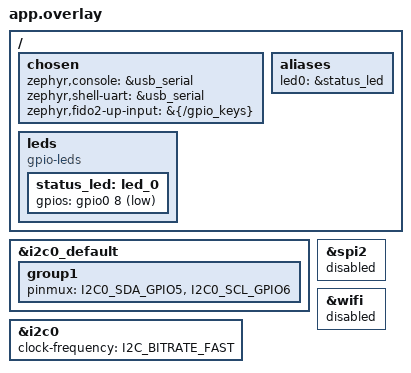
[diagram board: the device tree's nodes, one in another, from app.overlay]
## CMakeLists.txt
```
# SPDX-License-Identifier: Apache-2.0
cmake_minimum_required(VERSION 3.28.0)
find_package(Zephyr REQUIRED HINTS $ENV{ZEPHYR_BASE})
project(diy_fido_ble)
set(U8G2_ROOT ${CMAKE_CURRENT_SOURCE_DIR}/../vendor/u8g2)
file(GLOB U8G2_SOURCES ${U8G2_ROOT}/csrc/*.c)
target_sources(app PRIVATE src/main.c src/oled.c src/user_presence.c src/key_import.c ${U8G2_SOURCES})
target_include_directories(app PRIVATE ${U8G2_ROOT}/csrc src)
```

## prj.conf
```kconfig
CONFIG_FIDO2=y
CONFIG_FIDO2_TRANSPORT_BLE=y
CONFIG_FIDO2_AAGUID="25497c3c8433453eacfc9dd2c04e8e15"
CONFIG_FIDO2_BLE_REQUIRE_AUTHENTICATED_LINK=y
CONFIG_FIDO2_UP_CUSTOM=y
CONFIG_FIDO2_LOG_LEVEL_INF=y
CONFIG_BT=y
CONFIG_BT_PERIPHERAL=y
CONFIG_BT_SMP=y
CONFIG_BT_SETTINGS=y
CONFIG_BT_BONDING_REQUIRED=y
# Keep bonds for five PCs; a sixth must not silently evict an existing PC.
CONFIG_BT_MAX_PAIRED=5
CONFIG_BT_MAX_CONN=1
CONFIG_BT_KEYS_OVERWRITE_OLDEST=n
CONFIG_BT_USER_CONN_PARAM_REJECTED=y
CONFIG_BT_GATT_ENFORCE_SUBSCRIPTION=y
CONFIG_BT_DIS=y
CONFIG_BT_DIS_FW_REV=y
CONFIG_BT_DIS_MANUF_NAME_STR="DIY FIDO"
CONFIG_BT_DIS_MODEL_NUMBER_STR="ESP32-C3 OLED"
CONFIG_BT_DIS_FW_REV_STR="0.1"
CONFIG_BT_DEVICE_NAME="DIY FIDO C3"
CONFIG_BT_RX_STACK_SIZE=3072
CONFIG_BT_PERIPHERAL_PREF_MIN_INT=24
CONFIG_BT_PERIPHERAL_PREF_MAX_INT=40
CONFIG_BT_PERIPHERAL_PREF_LATENCY=0
CONFIG_BT_PERIPHERAL_PREF_TIMEOUT=400
CONFIG_FLASH=y
CONFIG_FLASH_MAP=y
CONFIG_NVS=y
CONFIG_SETTINGS=y
CONFIG_SETTINGS_NVS=y
CONFIG_SECURE_STORAGE_ITS_MAX_DATA_SIZE=1024
CONFIG_GPIO=y
CONFIG_INPUT=y
CONFIG_I2C=y
CONFIG_LOG=y
CONFIG_SERIAL=y
CONFIG_CONSOLE=y
CONFIG_UART_CONSOLE=y
CONFIG_MAIN_STACK_SIZE=8192
CONFIG_SYSTEM_WORKQUEUE_STACK_SIZE=4096
CONFIG_HEAP_MEM_POOL_SIZE=32768

# Crypto and controller tasks need headroom on the ESP32-C3 port.
CONFIG_FIDO2_THREAD_STACK_SIZE=8192
CONFIG_ESP32_BT_CONTROLLER_STACK_SIZE=8192
CONFIG_STACK_SENTINEL=y
CONFIG_INIT_STACKS=y
CONFIG_LOG_BUFFER_SIZE=4096

CONFIG_REBOOT=y
```

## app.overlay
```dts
#include <zephyr/dt-bindings/pinctrl/esp32c3-pinctrl.h>

/ {
    chosen {
        zephyr,console = &usb_serial;
        zephyr,shell-uart = &usb_serial;
        zephyr,fido2-up-input = &{/gpio_keys};
    };
    aliases {
        led0 = &status_led;
    };
    leds {
        compatible = "gpio-leds";
        status_led: led_0 {
            gpios = <&gpio0 8 GPIO_ACTIVE_LOW>;
        };
    };
};

&i2c0_default {
    group1 {
        pinmux = <I2C0_SDA_GPIO5>, <I2C0_SCL_GPIO6>;
    };
};

&i2c0 { clock-frequency = <I2C_BITRATE_FAST>; };

&spi2 { status = "disabled"; };
&wifi { status = "disabled"; };
```

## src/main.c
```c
/* SPDX-License-Identifier: Apache-2.0 */
#include <zephyr/kernel.h>
#include <zephyr/logging/log.h>
#include <zephyr/drivers/gpio.h>
#include <zephyr/bluetooth/bluetooth.h>
#include <zephyr/bluetooth/conn.h>
#include <zephyr/bluetooth/uuid.h>
#include <zephyr/settings/settings.h>
#include <zephyr/authentication/fido2/fido2.h>
#include <zephyr/authentication/fido2/fido2_transport.h>
#include <zephyr/sys/atomic.h>
#include <stdio.h>
#include <esp_bt.h>
#include <zephyr/input/input.h>
#include "oled.h"
#include "key_import.h"

LOG_MODULE_REGISTER(diy_fido, LOG_LEVEL_INF);
static const struct gpio_dt_spec led = GPIO_DT_SPEC_GET(DT_ALIAS(led0), gpios);
static K_MUTEX_DEFINE(pairing_lock);
static struct bt_conn *pairing_conn;
static atomic_t state;
static atomic_t passkey = ATOMIC_INIT(-1);
static atomic_t connected;
static atomic_t comparison_pressed;

static void comparison_button(struct input_event *evt, void *data)
{
    ARG_UNUSED(data);
    if (evt->type == INPUT_EV_KEY && evt->code == INPUT_KEY_0 &&
        evt->value == 1 && atomic_get(&passkey) >= 0) {
        atomic_set(&comparison_pressed, 1);
    }
}
INPUT_CALLBACK_DEFINE(DEVICE_DT_GET(DT_CHOSEN(zephyr_fido2_up_input)),
                      comparison_button, NULL);
static void clear_pairing(void);

static const struct bt_data ad[] = {
    BT_DATA_BYTES(BT_DATA_FLAGS, BT_LE_AD_GENERAL | BT_LE_AD_NO_BREDR),
    BT_DATA_BYTES(BT_DATA_UUID16_ALL, BT_UUID_16_ENCODE(FIDO2_BLE_SERVICE_UUID_VAL)),
};
static const uint8_t service_data[] = {
    BT_UUID_16_ENCODE(FIDO2_BLE_SERVICE_UUID_VAL), FIDO2_BLE_SERVICE_DATA_PAIRING_MODE,
};
static const struct bt_data sd[] = {
    BT_DATA(BT_DATA_SVC_DATA16, service_data, sizeof(service_data)),
    BT_DATA(BT_DATA_NAME_COMPLETE, CONFIG_BT_DEVICE_NAME, sizeof(CONFIG_BT_DEVICE_NAME) - 1),
};

static void advertise(void)
{
    int err = bt_le_adv_start(BT_LE_ADV_CONN_FAST_1, ad, ARRAY_SIZE(ad), sd, ARRAY_SIZE(sd));
    LOG_INF("BLE advertising result=%d", err);
}
static void on_connected(struct bt_conn *conn, uint8_t err)
{
    ARG_UNUSED(conn);
    atomic_set(&connected, err == 0);
    LOG_INF("BLE connected result=%u", err);
    if (err == 0) {
        int security_err = bt_conn_set_security(conn, BT_SECURITY_L3);
        LOG_INF("BLE security request=%d", security_err);
    }
}
static void on_disconnected(struct bt_conn *conn, uint8_t reason)
{
    ARG_UNUSED(conn);
    atomic_clear(&connected);
    clear_pairing();
    LOG_INF("BLE disconnected reason=%u", reason);
}
static void on_recycled(void) { advertise(); }
static void on_security(struct bt_conn *conn, bt_security_t level, enum bt_security_err err)
{
    ARG_UNUSED(conn);
    LOG_INF("BLE security level=%u result=%u", level, err);
}
BT_CONN_CB_DEFINE(connection_callbacks) = {
    .connected = on_connected, .disconnected = on_disconnected, .recycled = on_recycled,
    .security_changed = on_security,
};

static void display_passkey(struct bt_conn *conn, unsigned int key)
{
    ARG_UNUSED(conn);
    atomic_set(&passkey, key);
    LOG_INF("BLE pairing: passkey shown on OLED");
}
static void confirm_passkey(struct bt_conn *conn, unsigned int key)
{
    k_mutex_lock(&pairing_lock, K_FOREVER);
    if (pairing_conn) { bt_conn_unref(pairing_conn); }
    pairing_conn = bt_conn_ref(conn);
    atomic_clear(&comparison_pressed);
    atomic_set(&passkey, key);
    k_mutex_unlock(&pairing_lock);
    LOG_INF("BLE numeric comparison: compare OLED PIN and press BOOT");
}
static void clear_pairing(void)
{
    k_mutex_lock(&pairing_lock, K_FOREVER);
    if (pairing_conn) { bt_conn_unref(pairing_conn); pairing_conn = NULL; }
    atomic_set(&passkey, -1);
    atomic_clear(&comparison_pressed);
    k_mutex_unlock(&pairing_lock);
}
static void pairing_cancel(struct bt_conn *conn)
{
    ARG_UNUSED(conn);
    clear_pairing();
}
static void pairing_complete(struct bt_conn *conn, bool bonded)
{
    ARG_UNUSED(conn);
    clear_pairing();
    LOG_INF("BLE pairing completed bonded=%d", bonded);
}
static void pairing_failed(struct bt_conn *conn, enum bt_security_err reason)
{
    ARG_UNUSED(conn);
    clear_pairing();
    LOG_WRN("BLE pairing failed reason=%u", reason);
}
static const struct bt_conn_auth_cb auth_callbacks = {
    .passkey_display = display_passkey, .passkey_confirm = confirm_passkey,
    .cancel = pairing_cancel,
};
static struct bt_conn_auth_info_cb auth_info_callbacks = {
    .pairing_complete = pairing_complete, .pairing_failed = pairing_failed,
};

static void state_changed(enum fido2_runtime_state current, void *data)
{
    ARG_UNUSED(data);
    atomic_set(&state, current);
    LOG_INF("FIDO state=%d", current);
}

int main(void)
{
    int err;
    oled_init();
    gpio_pin_configure_dt(&led, GPIO_OUTPUT_INACTIVE);
    err = fido2_init();
    if (err) { LOG_ERR("FIDO init=%d", err); oled_status("Init failed", "See USB log"); return err; }
    key_import_boot_mode();
    fido2_set_state_callback(state_changed, NULL);
    err = fido2_start();
    if (err) { return err; }
    bt_conn_auth_cb_register(&auth_callbacks);
    bt_conn_auth_info_cb_register(&auth_info_callbacks);
    err = bt_enable(NULL);
    if (err) { LOG_ERR("BLE init=%d", err); return err; }
    err = settings_load();
    if (err) { LOG_ERR("Settings load=%d", err); return err; }
    err = esp_ble_tx_power_set(ESP_BLE_PWR_TYPE_DEFAULT, ESP_PWR_LVL_P9);
    LOG_INF("BLE default TX power +9 dBm result=%d", err);
    err = esp_ble_tx_power_set(ESP_BLE_PWR_TYPE_ADV, ESP_PWR_LVL_P9);
    LOG_INF("BLE advertising TX power +9 dBm result=%d", err);
    advertise();
    LOG_INF("DIY FIDO2 BLE ready: BOOT confirms presence; OLED shows pairing PIN");
    unsigned int tick = 0;
    int last_key = -2, last_state = -1, last_connected = -1;
    while (1) {
        char detail[16];
        int key = atomic_get(&passkey);
        int current = atomic_get(&state);
        int link = atomic_get(&connected);
        if (atomic_cas(&comparison_pressed, 1, 0)) {
            k_mutex_lock(&pairing_lock, K_FOREVER);
            struct bt_conn *confirm = pairing_conn;
            pairing_conn = NULL;
            k_mutex_unlock(&pairing_lock);
            if (confirm) {
                int result = bt_conn_auth_passkey_confirm(confirm);
                LOG_INF("BOOT confirmed BLE comparison result=%d", result);
                bt_conn_unref(confirm);
            }
        }
        if (key != last_key || current != last_state || link != last_connected) {
            if (key >= 0) {
                snprintf(detail, sizeof(detail), "%06d", key);
                oled_status("PIN + BOOT", detail);
            } else if (current == FIDO2_RUNTIME_STATE_WAITING_USER_PRESENCE) {
                oled_status("Press BOOT", "Confirm now");
            } else if (current == FIDO2_RUNTIME_STATE_PROCESSING) {
                oled_status("Processing", "Please wait");
            } else {
                oled_status("Ready", link ? "Connected" : "Pair via BLE");
            }
            last_key = key;
            last_state = current;
            last_connected = link;
        }
        gpio_pin_set_dt(&led, current == FIDO2_RUNTIME_STATE_PROCESSING ||
            (current == FIDO2_RUNTIME_STATE_WAITING_USER_PRESENCE && tick % 2));
        tick++;
        k_msleep(200);
    }
}
```

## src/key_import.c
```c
/* SPDX-License-Identifier: Apache-2.0 */
#include <zephyr/kernel.h>
#include <zephyr/drivers/gpio.h>
#include <zephyr/drivers/uart.h>
#include <zephyr/sys/byteorder.h>
#include <zephyr/sys/printk.h>
#include <zephyr/sys/reboot.h>
#include <zephyr/random/random.h>
#include <zephyr/psa/key_ids.h>
#include <zephyr/authentication/fido2/fido2_storage.h>
#include <zephyr/input/input.h>
#include <zephyr/sys/atomic.h>
#include <psa/crypto.h>
#include <mbedtls/platform_util.h>
#include <string.h>
#include "oled.h"
#include "key_import.h"

static const struct gpio_dt_spec button = GPIO_DT_SPEC_GET(DT_ALIAS(sw0), gpios);
static const struct device *const serial = DEVICE_DT_GET(DT_CHOSEN(zephyr_console));
static uint8_t packet[359]; /* lengths(3), count(4), scalar(32), RP(127), user(64), ID(128) */
static struct fido2_credential imported;
static K_SEM_DEFINE(import_pressed, 0, 1);
static atomic_t awaiting_import;

static void import_button(struct input_event *evt, void *data)
{
    ARG_UNUSED(data);
    if (evt->type == INPUT_EV_KEY && evt->code == INPUT_KEY_0 &&
        evt->value == 1 && atomic_get(&awaiting_import)) {
        k_sem_give(&import_pressed);
    }
}
INPUT_CALLBACK_DEFINE(DEVICE_DT_GET(DT_CHOSEN(zephyr_fido2_up_input)), import_button, NULL);

static void send_text(const char *text)
{
    while (*text) { uart_poll_out(serial, *text++); }
}
static int read_exact(uint8_t *data, size_t len, int64_t deadline)
{
    for (size_t i = 0; i < len;) {
        if (k_uptime_get() > deadline) { return -ETIMEDOUT; }
        if (uart_poll_in(serial, &data[i]) == 0) { i++; }
        else { k_msleep(1); }
    }
    return 0;
}
static int import_packet(size_t length, uint8_t public_key[65])
{
    uint8_t rp_len = packet[0], user_len = packet[1], id_len = packet[2];
    if (length < 39 || !rp_len || rp_len >= sizeof(imported.rp_id) ||
        !user_len || user_len > sizeof(imported.user_id) ||
        !id_len || id_len > sizeof(imported.id) ||
        length != (size_t)39 + rp_len + user_len + id_len) { return -EINVAL; }
    /* Accept a lowercase ASCII RP identifier, never a URL or embedded NUL. */
    for (size_t i = 39; i < 39 + rp_len; i++) {
        uint8_t c = packet[i];
        if (!((c >= 'a' && c <= 'z') || (c >= '0' && c <= '9') || c == '-' || c == '.')) {
            return -EINVAL;
        }
    }
    memcpy(imported.id, packet + 39 + rp_len + user_len, id_len);
    imported.id_len = id_len;
    struct fido2_credential existing;
    int err = fido2_storage_load(imported.id, id_len, &existing);
    mbedtls_platform_zeroize(&existing, sizeof(existing));
    if (err == 0) { return -EEXIST; }
    if (err != -ENOENT) { return err; }
    memcpy(imported.rp_id, packet + 39, rp_len);
    memcpy(imported.user_id, packet + 39 + rp_len, user_len);
    imported.user_id_len = user_len;
    imported.sign_count = sys_get_be32(packet + 3);
    if (imported.sign_count == UINT32_MAX) { return -EINVAL; }
    imported.algorithm = FIDO2_COSE_ES256;
    imported.discoverable = true;
    strcpy(imported.user_name, "USB imported");
    strcpy(imported.user_display_name, "USB imported");
    size_t hash_len;
    if (psa_hash_compute(PSA_ALG_SHA_256, (uint8_t *)imported.rp_id, rp_len,
                         imported.rp_id_hash, 32, &hash_len) != PSA_SUCCESS) { return -EIO; }
    oled_status("Import? BOOT", imported.rp_id);
    send_text("\nDFI:CONFIRM\n");
    /* Require a released button followed by a fresh physical press. */
    int64_t release_deadline = k_uptime_get() + 30000;
    while (gpio_pin_get_dt(&button) == 1) {
        if (k_uptime_get() > release_deadline) { return -ETIMEDOUT; }
        k_msleep(10);
    }
    k_sem_reset(&import_pressed);
    atomic_set(&awaiting_import, 1);
    err = k_sem_take(&import_pressed, K_SECONDS(120));
    atomic_clear(&awaiting_import);
    if (err) { return -EACCES; }
    psa_status_t status = PSA_ERROR_ALREADY_EXISTS;
    for (int i = 0; i < 32 && status == PSA_ERROR_ALREADY_EXISTS; i++) {
        psa_key_attributes_t attr = PSA_KEY_ATTRIBUTES_INIT;
        psa_key_id_t candidate = ZEPHYR_PSA_FIDO2_KEY_ID_RANGE_BEGIN + 1 +
            sys_rand32_get() % (ZEPHYR_PSA_FIDO2_KEY_ID_RANGE_SIZE - 1);
        psa_set_key_type(&attr, PSA_KEY_TYPE_ECC_KEY_PAIR(PSA_ECC_FAMILY_SECP_R1));
        psa_set_key_bits(&attr, 256);
        psa_set_key_usage_flags(&attr, PSA_KEY_USAGE_SIGN_HASH);
        psa_set_key_algorithm(&attr, PSA_ALG_ECDSA(PSA_ALG_SHA_256));
        psa_set_key_lifetime(&attr, PSA_KEY_LIFETIME_PERSISTENT);
        psa_set_key_id(&attr, candidate);
        status = psa_import_key(&attr, packet + 7, 32, &imported.key_id);
        psa_reset_key_attributes(&attr);
    }
    mbedtls_platform_zeroize(packet + 7, 32);
    if (status != PSA_SUCCESS) { return -EIO; }
    size_t public_len;
    status = psa_export_public_key(imported.key_id, public_key, 65, &public_len);
    if (status != PSA_SUCCESS || public_len != 65) { err = -EIO; }
    else { err = fido2_storage_store(&imported); }
    if (err) { psa_destroy_key(imported.key_id); }
    return err;
}
void key_import_boot_mode(void)
{
    oled_status("Starting", "USB window 5s");
    send_text("\nDFI:READY\n");
    uint8_t header[6], public_key[65] = {0};
    int err = read_exact(header, sizeof(header), k_uptime_get() + 5000);
    if (err == -ETIMEDOUT) { return; }
    if (!err && memcmp(header, "DFI1", 4)) { err = -EINVAL; }
    size_t length = err ? 0 : sys_get_be16(header + 4);
    if (!err && (length < 39 || length > sizeof(packet))) { err = -EINVAL; }
    if (!err) { err = read_exact(packet, length, k_uptime_get() + 10000); }
    if (!err) { err = import_packet(length, public_key); }
    mbedtls_platform_zeroize(packet, sizeof(packet));
    mbedtls_platform_zeroize(&imported, sizeof(imported));
    if (err) {
        char failure[32];
        snprintk(failure, sizeof(failure), "\nDFI:ERROR:%d\n", err);
        send_text(failure); oled_status("Import failed", "Restart normal");
    } else {
        static const char hex[] = "0123456789abcdef";
        send_text("\nDFI:OK:");
        for (size_t i = 0; i < sizeof(public_key); i++) {
            uart_poll_out(serial, hex[public_key[i] >> 4]);
            uart_poll_out(serial, hex[public_key[i] & 15]);
        }
        send_text("\n"); oled_status("Imported", "Restart normal");
    }
    k_msleep(500);
    sys_reboot(SYS_REBOOT_COLD);
    while (1) { k_msleep(1000); }
}
```

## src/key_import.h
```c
/* SPDX-License-Identifier: Apache-2.0 */
#pragma once
/* Offers a brief USB import window before BLE starts. */
void key_import_boot_mode(void);
```

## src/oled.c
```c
/* SPDX-License-Identifier: Apache-2.0 */
#include <zephyr/kernel.h>
#include <zephyr/drivers/i2c.h>
#include <u8g2.h>
#include "oled.h"

static const struct device *bus = DEVICE_DT_GET(DT_NODELABEL(i2c0));
static u8g2_t oled;
static uint8_t tx[32];
static size_t tx_len;
static bool ready;

static uint8_t byte_cb(u8x8_t *display, uint8_t msg, uint8_t len, void *data)
{
    switch (msg) {
    case U8X8_MSG_BYTE_INIT: return device_is_ready(bus);
    case U8X8_MSG_BYTE_START_TRANSFER: tx_len = 0; return 1;
    case U8X8_MSG_BYTE_SEND:
        if (tx_len + len > sizeof(tx)) { return 0; }
        memcpy(tx + tx_len, data, len);
        tx_len += len;
        return 1;
    case U8X8_MSG_BYTE_END_TRANSFER:
        return i2c_write(bus, tx, tx_len, u8x8_GetI2CAddress(display) >> 1) == 0;
    case U8X8_MSG_BYTE_SET_DC: return 1;
    default: return 0;
    }
}

static uint8_t delay_cb(u8x8_t *display, uint8_t msg, uint8_t arg, void *data)
{
    ARG_UNUSED(display); ARG_UNUSED(data);
    switch (msg) {
    case U8X8_MSG_GPIO_AND_DELAY_INIT: return 1;
    case U8X8_MSG_DELAY_MILLI: k_msleep(arg); return 1;
    case U8X8_MSG_DELAY_10MICRO: k_busy_wait(arg * 10); return 1;
    case U8X8_MSG_DELAY_NANO: k_busy_wait(1); return 1;
    default: return 1;
    }
}

int oled_init(void)
{
    if (!device_is_ready(bus)) { return -ENODEV; }
    u8g2_Setup_ssd1306_i2c_128x64_noname_f(&oled, U8G2_R0, byte_cb, delay_cb);
    u8g2_SetI2CAddress(&oled, 0x3c << 1);
    u8g2_InitDisplay(&oled);
    u8g2_SetPowerSave(&oled, 0);
    u8g2_SetContrast(&oled, 128);
    ready = true;
    oled_status("Starting", "Zephyr BLE");
    return 0;
}

void oled_status(const char *state, const char *detail)
{
    if (!ready) { return; }
    u8g2_ClearBuffer(&oled);
    u8g2_SetFont(&oled, u8g2_font_5x7_tr);
    u8g2_DrawFrame(&oled, 28, 24, 72, 40);
    u8g2_DrawStr(&oled, 31, 34, "FIDO2 BLE");
    u8g2_DrawStr(&oled, 31, 46, state);
    u8g2_DrawStr(&oled, 31, 58, detail);
    u8g2_SendBuffer(&oled);
}
```

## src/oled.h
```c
/* SPDX-License-Identifier: Apache-2.0 */
#pragma once
int oled_init(void);
void oled_status(const char *state, const char *detail);
```

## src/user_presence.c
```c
/* SPDX-License-Identifier: Apache-2.0 */
#include <zephyr/kernel.h>
#include <zephyr/input/input.h>
#include <zephyr/authentication/fido2/fido2_up.h>
#include <zephyr/sys/atomic.h>

static K_SEM_DEFINE(pressed, 0, 1);
static atomic_t cancelled;
static atomic_t awaiting_press;

static void button_cb(struct input_event *evt, void *data)
{
    ARG_UNUSED(data);
    /* Only a new physical press during the request can approve it. */
    if (evt->type == INPUT_EV_KEY && evt->code == INPUT_KEY_0 && evt->value == 1 &&
        atomic_get(&awaiting_press)) {
        k_sem_give(&pressed);
    }
}
INPUT_CALLBACK_DEFINE(DEVICE_DT_GET(DT_CHOSEN(zephyr_fido2_up_input)), button_cb, NULL);

void fido2_up_reset(void)
{
    atomic_clear(&awaiting_press);
    atomic_clear(&cancelled);
    k_sem_reset(&pressed);
}

int fido2_up_wait(void)
{
    atomic_set(&awaiting_press, 1);
    int err = k_sem_take(&pressed, K_MSEC(CONFIG_FIDO2_UP_TIMEOUT_MS));
    atomic_clear(&awaiting_press);
    if (atomic_get(&cancelled)) { return -ECANCELED; }
    return err ? -ETIMEDOUT : 0;
}

void fido2_up_cancel(void)
{
    atomic_set(&cancelled, 1);
    k_sem_give(&pressed);
}
```
